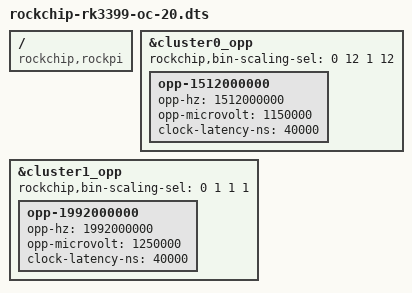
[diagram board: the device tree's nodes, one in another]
/dts-v1/;
/plugin/;

/ {
	compatible = "rockchip,rockpi","rockchip,rk3399";

	fragment@0 {
		target = <&cluster0_opp>;

		__overlay__ {
			rockchip,bin-scaling-sel = <
				0	12
				1	12
			>;
			opp-1512000000 {
				opp-hz = /bits/ 64 <1512000000>;
				opp-microvolt = <1150000>;
				clock-latency-ns = <40000>;
			};
		};
	};

	fragment@1 {
		target = <&cluster1_opp>;

		__overlay__ {
			rockchip,bin-scaling-sel = <
				0	1
				1	1
			>;
			opp-1992000000 {
				opp-hz = /bits/ 64 <1992000000>;
				opp-microvolt = <1250000>;
				clock-latency-ns = <40000>;
			};
		};
	};
};
